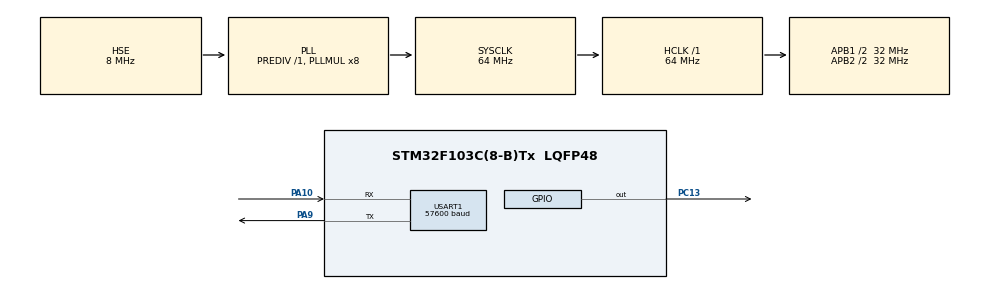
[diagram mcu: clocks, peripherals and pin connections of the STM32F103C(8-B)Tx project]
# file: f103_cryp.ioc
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Mcu.Family=STM32F1
RCC.PLLSourceVirtual=RCC_PLLSOURCE_HSE
PD1-OSC_OUT.Mode=HSE-External-Oscillator
PA10.Mode=Asynchronous
USART1.BaudRate=57600
PC13-TAMPER-RTC.Signal=GPIO_Output
PD0-OSC_IN.Signal=RCC_OSC_IN
RCC.APB1CLKDivider=RCC_HCLK_DIV2
VP_SYS_VS_ND.Mode=No_Debug
RCC.SYSCLKSource=RCC_SYSCLKSOURCE_PLLCLK
ProjectManager.StackSize=0x400
PD1-OSC_OUT.Signal=RCC_OSC_OUT
PA9.Mode=Asynchronous
ProjectManager.TargetToolchain=STM32CubeIDE
RCC.HCLKFreq_Value=64000000
RCC.APB2TimFreq_Value=64000000
PA9.Signal=USART1_TX
RCC.USBFreq_Value=64000000
RCC.AHBFreq_Value=64000000
PD0-OSC_IN.Mode=HSE-External-Oscillator
board=custom
RCC.PLLMUL=RCC_PLL_MUL8
RCC.APB2Freq_Value=32000000
Mcu.Name=STM32F103C(8-B)Tx
RCC.SYSCLKFreq_VALUE=64000000
Mcu.Package=LQFP48
USART1.VirtualMode=VM_ASYNC
PA10.Signal=USART1_RX
ProjectManager.HeapSize=0x200
NVIC.PriorityGroup=NVIC_PRIORITYGROUP_4
RCC.APB2CLKDivider=RCC_HCLK_DIV2
RCC.APB1TimFreq_Value=64000000
RCC.APB1Freq_Value=32000000

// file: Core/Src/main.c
/* USER CODE BEGIN Header */
/**
  ******************************************************************************
  * @file           : main.c
  * @brief          : Main program body
  ******************************************************************************
  * @attention
  *
  * <h2><center>&copy; Copyright (c) 2021 STMicroelectronics.
  * All rights reserved.</center></h2>
  *
  * This software component is licensed by ST under BSD 3-Clause license,
  * the "License"; You may not use this file except in compliance with the
  * License. You may obtain a copy of the License at:
  *                        opensource.org/licenses/BSD-3-Clause
  *
  ******************************************************************************
  */
/* USER CODE END Header */
#include "main.h"

/* USER CODE BEGIN PTD */
typedef enum {FAILED = 0, PASSED = !FAILED} TestStatus;
/* USER CODE END PTD */

/* USER CODE BEGIN PD */
#define PLAINTEXT_LENGTH 64
/* USER CODE END PD */

UART_HandleTypeDef huart1;

/* USER CODE BEGIN PV */
const uint8_t Plaintext[PLAINTEXT_LENGTH] =
  {
    0x6b, 0xc1, 0xbe, 0xe2, 0x2e, 0x40, 0x9f, 0x96,
    0xe9, 0x3d, 0x7e, 0x11, 0x73, 0x93, 0x17, 0x2a,
    0xae, 0x2d, 0x8a, 0x57, 0x1e, 0x03, 0xac, 0x9c,
    0x9e, 0xb7, 0x6f, 0xac, 0x45, 0xaf, 0x8e, 0x51,
    0x30, 0xc8, 0x1c, 0x46, 0xa3, 0x5c, 0xe4, 0x11,
    0xe5, 0xfb, 0xc1, 0x19, 0x1a, 0x0a, 0x52, 0xef,
    0xf6, 0x9f, 0x24, 0x45, 0xdf, 0x4f, 0x9b, 0x17,
    0xad, 0x2b, 0x41, 0x7b, 0xe6, 0x6c, 0x37, 0x10
  };

/* Key to be used for AES encryption/decryption */
uint8_t Key[CRL_AES256_KEY] =
  {
    0x60, 0x3d, 0xeb, 0x10, 0x15, 0xca, 0x71, 0xbe,
    0x2b, 0x73, 0xae, 0xf0, 0x85, 0x7d, 0x77, 0x81,
    0x1f, 0x35, 0x2c, 0x07, 0x3b, 0x61, 0x08, 0xd7,
    0x2d, 0x98, 0x10, 0xa3, 0x09, 0x14, 0xdf, 0xf4,
  };

/* Buffer to store the output data */
uint8_t OutputMessage[PLAINTEXT_LENGTH];

/* Size of the output data */
uint32_t OutputMessageLength = 0;

const uint8_t Expected_Ciphertext[PLAINTEXT_LENGTH] =
  {
    0xf3, 0xee, 0xd1, 0xbd, 0xb5, 0xd2, 0xa0, 0x3c,
    0x06, 0x4b, 0x5a, 0x7e, 0x3d, 0xb1, 0x81, 0xf8,
    0x59, 0x1c, 0xcb, 0x10, 0xd4, 0x10, 0xed, 0x26,
    0xdc, 0x5b, 0xa7, 0x4a, 0x31, 0x36, 0x28, 0x70,
    0xb6, 0xed, 0x21, 0xb9, 0x9c, 0xa6, 0xf4, 0xf9,
    0xf1, 0x53, 0xe7, 0xb1, 0xbe, 0xaf, 0xed, 0x1d,
    0x23, 0x30, 0x4b, 0x7a, 0x39, 0xf9, 0xf3, 0xff,
    0x06, 0x7d, 0x8d, 0x8f, 0x9e, 0x24, 0xec, 0xc7
  };

/* USER CODE END PV */

void SystemClock_Config(void);
static void MX_GPIO_Init(void);
static void MX_USART1_UART_Init(void);
/* USER CODE BEGIN PFP */
int32_t STM32_AES_ECB_Encrypt(uint8_t* InputMessage,
                              uint32_t InputMessageLength,
                              uint8_t  *AES256_Key,
                              uint8_t  *OutputMessage,
                              uint32_t *OutputMessageLength);

int32_t STM32_AES_ECB_Decrypt(uint8_t* InputMessage,
                              uint32_t InputMessageLength,
                              uint8_t *AES256_Key,
                              uint8_t  *OutputMessage,
                              uint32_t *OutputMessageLength);
TestStatus Buffercmp(const uint8_t* pBuffer,
                     uint8_t* pBuffer1,
                     uint16_t BufferLength);

/* USER CODE END PFP */

/* USER CODE BEGIN 0 */
/* Encrypt DATA with AES in ECB mode */

/* USER CODE END 0 */

int main(void)
{
  /* USER CODE BEGIN 1 */
	int32_t status = AES_SUCCESS;
  /* USER CODE END 1 */

  /* MCU Configuration--------------------------------------------------------*/

  /* Reset of all peripherals, Initializes the Flash interface and the Systick. */
  HAL_Init();

  /* Configure the system clock */
  SystemClock_Config();

  /* Initialize all configured peripherals */
  MX_GPIO_Init();
  MX_USART1_UART_Init();
  /* USER CODE BEGIN 2 */

  /* Enable CRC clock */
   __CRC_CLK_ENABLE();

  status = STM32_AES_ECB_Encrypt( (uint8_t *) Plaintext, PLAINTEXT_LENGTH, Key, OutputMessage,
                                  &OutputMessageLength);
  if (status == AES_SUCCESS)
  {
    if (Buffercmp(Expected_Ciphertext, OutputMessage, PLAINTEXT_LENGTH) == PASSED)
    {

      /* add application traitment in case of AES ECB encryption is passed */
    }
    else
    {
      Error_Handler();
    }
  }
  else
  {

    /* In case of encryption/decryption not success the possible values of status:
     * AES_ERR_BAD_CONTEXT, AES_ERR_BAD_PARAMETER, AES_ERR_BAD_INPUT_SIZE, AES_ERR_BAD_OPERATION
     */
    Error_Handler();
  }
  /* Decrypt DATA with AES in ECB mode */
  status = STM32_AES_ECB_Decrypt( (uint8_t *) Expected_Ciphertext, PLAINTEXT_LENGTH, Key, OutputMessage,
                                  &OutputMessageLength);
  if (status == AES_SUCCESS)
  {
    if (Buffercmp(Plaintext, OutputMessage, PLAINTEXT_LENGTH) == PASSED)
    {
      /* add application traitment in case of AES ECB encryption is passed */
    }
    else
    {
      Error_Handler();

    }
  }
  else
  {
    /* In case of encryption/decryption not success the possible values of status:
     * AES_ERR_BAD_CONTEXT, AES_ERR_BAD_PARAMETER, AES_ERR_BAD_INPUT_SIZE, AES_ERR_BAD_OPERATION
     */

    Error_Handler();
  }
  /* USER CODE END 2 */

  /* Infinite loop */
  while (1)
  {

  }
}

void SystemClock_Config(void)
{
  RCC_OscInitTypeDef RCC_OscInitStruct = {0};
  RCC_ClkInitTypeDef RCC_ClkInitStruct = {0};

  /** Initializes the RCC Oscillators according to the specified parameters
  * in the RCC_OscInitTypeDef structure.
  */
  RCC_OscInitStruct.OscillatorType = RCC_OSCILLATORTYPE_HSE;
  RCC_OscInitStruct.HSEState = RCC_HSE_ON;
  RCC_OscInitStruct.HSEPredivValue = RCC_HSE_PREDIV_DIV1;
  RCC_OscInitStruct.HSIState = RCC_HSI_ON;
  RCC_OscInitStruct.PLL.PLLState = RCC_PLL_ON;
  RCC_OscInitStruct.PLL.PLLSource = RCC_PLLSOURCE_HSE;
  RCC_OscInitStruct.PLL.PLLMUL = RCC_PLL_MUL8;
  if (HAL_RCC_OscConfig(&RCC_OscInitStruct) != HAL_OK)
  {
    Error_Handler();
  }
  /** Initializes the CPU, AHB and APB buses clocks
  */
  RCC_ClkInitStruct.ClockType = RCC_CLOCKTYPE_HCLK|RCC_CLOCKTYPE_SYSCLK
                              |RCC_CLOCKTYPE_PCLK1|RCC_CLOCKTYPE_PCLK2;
  RCC_ClkInitStruct.SYSCLKSource = RCC_SYSCLKSOURCE_PLLCLK;
  RCC_ClkInitStruct.AHBCLKDivider = RCC_SYSCLK_DIV1;
  RCC_ClkInitStruct.APB1CLKDivider = RCC_HCLK_DIV2;
  RCC_ClkInitStruct.APB2CLKDivider = RCC_HCLK_DIV2;

  if (HAL_RCC_ClockConfig(&RCC_ClkInitStruct, FLASH_LATENCY_2) != HAL_OK)
  {
    Error_Handler();
  }
}

static void MX_USART1_UART_Init(void)
{

  huart1.Instance = USART1;
  huart1.Init.BaudRate = 57600;
  huart1.Init.WordLength = UART_WORDLENGTH_8B;
  huart1.Init.StopBits = UART_STOPBITS_1;
  huart1.Init.Parity = UART_PARITY_NONE;
  huart1.Init.Mode = UART_MODE_TX_RX;
  huart1.Init.HwFlowCtl = UART_HWCONTROL_NONE;
  huart1.Init.OverSampling = UART_OVERSAMPLING_16;
  if (HAL_UART_Init(&huart1) != HAL_OK)
  {
    Error_Handler();
  }

}

static void MX_GPIO_Init(void)
{
  GPIO_InitTypeDef GPIO_InitStruct = {0};

  /* GPIO Ports Clock Enable */
  __HAL_RCC_GPIOC_CLK_ENABLE();
  __HAL_RCC_GPIOD_CLK_ENABLE();
  __HAL_RCC_GPIOA_CLK_ENABLE();

  /*Configure GPIO pin Output Level */
  HAL_GPIO_WritePin(GPIOC, GPIO_PIN_13, GPIO_PIN_RESET);

  /*Configure GPIO pin : PC13 */
  GPIO_InitStruct.Pin = GPIO_PIN_13;
  GPIO_InitStruct.Mode = GPIO_MODE_OUTPUT_PP;
  GPIO_InitStruct.Pull = GPIO_NOPULL;
  GPIO_InitStruct.Speed = GPIO_SPEED_FREQ_LOW;
  HAL_GPIO_Init(GPIOC, &GPIO_InitStruct);

}

/* USER CODE BEGIN 4 */
/**
  * @brief  AES ECB Encryption example.
  * @param  InputMessage: pointer to input message to be encrypted.
  * @param  InputMessageLength: input data message length in byte.
  * @param  AES128_Key: pointer to the AES key to be used in the operation
  * @param  OutputMessage: pointer to output parameter that will handle the encrypted message
  * @param  OutputMessageLength: pointer to encrypted message length.
  * @retval error status: can be AES_SUCCESS if success or one of
  *         AES_ERR_BAD_INPUT_SIZE, AES_ERR_BAD_OPERATION, AES_ERR_BAD_CONTEXT
  *         AES_ERR_BAD_PARAMETER if error occured.
  */
int32_t STM32_AES_ECB_Encrypt(uint8_t* InputMessage,
                              uint32_t InputMessageLength,
                              uint8_t  *AES256_Key,
                              uint8_t  *OutputMessage,
                              uint32_t *OutputMessageLength)
{
  AESECBctx_stt AESctx;

  uint32_t error_status = AES_SUCCESS;

  int32_t outputLength = 0;

  /* Set flag field to default value */
  AESctx.mFlags = E_SK_DEFAULT;

  /* Set key size to 32 (corresponding to AES-256) */
  AESctx.mKeySize = 32;

  /* Initialize the operation, by passing the key.
   * Third parameter is NULL because ECB doesn't use any IV */
  error_status = AES_ECB_Encrypt_Init (&AESctx, AES256_Key, NULL );

  /* check for initialization errors */
  if (error_status == AES_SUCCESS)
  {
    /* Encrypt Data */
    error_status = AES_ECB_Encrypt_Append(&AESctx,
                                          InputMessage,
                                          InputMessageLength,
                                          OutputMessage,
                                          &outputLength);

    if (error_status == AES_SUCCESS)
    {
      /* Write the number of data written*/
      *OutputMessageLength = outputLength;
      /* Do the Finalization */
      error_status = AES_ECB_Encrypt_Finish(&AESctx, OutputMessage + *OutputMessageLength, &outputLength);
      /* Add data written to the information to be returned */
      *OutputMessageLength += outputLength;
    }
  }

  return error_status;
}

/**
  * @brief  AES ECB Decryption example.
  * @param  InputMessage: pointer to input message to be decrypted.
  * @param  InputMessageLength: input data message length in byte.
  * @param  AES128_Key: pointer to the AES key to be used in the operation
  * @param  OutputMessage: pointer to output parameter that will handle the decrypted message
  * @param  OutputMessageLength: pointer to decrypted message length.
  * @retval error status: can be AES_SUCCESS if success or one of
  *         AES_ERR_BAD_INPUT_SIZE, AES_ERR_BAD_OPERATION, AES_ERR_BAD_CONTEXT
  *         AES_ERR_BAD_PARAMETER if error occured.
  */
int32_t STM32_AES_ECB_Decrypt(uint8_t* InputMessage,
                              uint32_t InputMessageLength,
                              uint8_t  *AES256_Key,
                              uint8_t  *OutputMessage,
                              uint32_t *OutputMessageLength)
{
  AESECBctx_stt AESctx;

  uint32_t error_status = AES_SUCCESS;

  int32_t outputLength = 0;

  /* Set flag field to default value */
  AESctx.mFlags = E_SK_DEFAULT;

  /* Set key size to 32 (corresponding to AES-256) */
  AESctx.mKeySize = 32;

  /* Initialize the operation, by passing the key.
   * Third parameter is NULL because ECB doesn't use any IV */
  error_status = AES_ECB_Decrypt_Init (&AESctx, AES256_Key, NULL );

  /* check for initialization errors */
  if (error_status == AES_SUCCESS)
  {
    /* Decrypt Data */
    error_status = AES_ECB_Decrypt_Append(&AESctx,
                                          InputMessage,
                                          InputMessageLength,
                                          OutputMessage,
                                          &outputLength);

    if (error_status == AES_SUCCESS)
    {
      /* Write the number of data written*/
      *OutputMessageLength = outputLength;
      /* Do the Finalization */
      error_status = AES_ECB_Decrypt_Finish(&AESctx, OutputMessage + *OutputMessageLength, &outputLength);
      /* Add data written to the information to be returned */
      *OutputMessageLength += outputLength;
    }
  }

  return error_status;
}

/**
  * @brief  Compares two buffers.
  * @param  pBuffer, pBuffer1: buffers to be compared.
  * @param  BufferLength: buffer's length
  * @retval PASSED: pBuffer identical to pBuffer1
  *         FAILED: pBuffer differs from pBuffer1
  */
TestStatus Buffercmp(const uint8_t* pBuffer, uint8_t* pBuffer1, uint16_t BufferLength)
{
  while (BufferLength--)
  {
    if (*pBuffer != *pBuffer1)
    {
      return FAILED;
    }

    pBuffer++;
    pBuffer1++;
  }

  return PASSED;
}

/* USER CODE END 4 */

void Error_Handler(void)
{
  __disable_irq();
  while (1)
  {
  }
}

/************************ (C) COPYRIGHT STMicroelectronics *****END OF FILE****/
